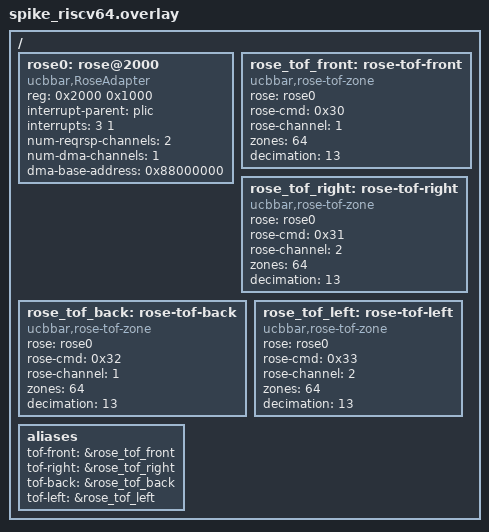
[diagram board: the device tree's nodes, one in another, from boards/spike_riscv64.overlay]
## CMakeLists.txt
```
# SPDX-License-Identifier: Apache-2.0
cmake_minimum_required(VERSION 3.20.0)
find_package(Zephyr REQUIRED HINTS $ENV{ZEPHYR_BASE})
project(rose_multisensor_probe)
target_sources(app PRIVATE src/main.c)
```

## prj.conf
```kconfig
# RoSE multizone-ToF data-collection probe (co-sim). Reads the 4 horizontal VL53L5CX zone
# grids over the RoSE bridge through the reusable ucbbar,rose-tof-zone driver.
CONFIG_SENSOR=y
CONFIG_PRINTK=y
CONFIG_BOOT_BANNER=n
# Match the (working) flight-controller image layout: with a tiny image __global_pointer$
# ends up >2KB from z_interrupt_stacks and the RISC-V GPREL relocation in the kernel's
# stacktrace code truncates at link. The C++ runtime + a large main stack grow .data/.bss
# so gp lands in range (spike_riscv64 forces the RISCV_GP choice on).
CONFIG_CPP=y
CONFIG_REQUIRES_FULL_LIBCPP=n
CONFIG_MAIN_STACK_SIZE=327680
```

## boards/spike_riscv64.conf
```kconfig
# RoSE co-sim: bridge driver + protocol + the multizone ToF virtual driver (bound by
# boards/spike_riscv64.overlay).
CONFIG_ROSE=y
CONFIG_ROSE_PROTOCOL=y
CONFIG_ROSE_SENSOR_TOF_ZONE=y

CONFIG_PICOLIBC=y
CONFIG_COMMON_LIBC_MALLOC=y
CONFIG_FPU=y
```

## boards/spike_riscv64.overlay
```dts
/* RoSE co-sim overlay for the multizone-ToF probe: the RoSE bridge adapter + the four
 * horizontal VL53L5CX multizone ToF sensors. Command IDs / reqrsp channels match
 * config_gym_IsaacCrazyflieMultiSensorEnv-v0.yaml (front 0x30/ch1, right 0x31/ch2,
 * back 0x32/ch1, left 0x33/ch2). The app binds them through the aliases tof_front/right/
 * back/left, exactly as a real board would bind st,vl53l5cx.
 */
/ {
	rose0: rose@2000 {
		compatible = "ucbbar,RoseAdapter";
		reg = <0x2000 0x1000>;
		interrupt-parent = <&plic>;
		interrupts = <3 1>;
		num-reqrsp-channels = <2>;
		num-dma-channels = <1>;
		dma-base-address = <0x88000000>;
		status = "okay";
	};

	rose_tof_front: rose-tof-front {
		compatible = "ucbbar,rose-tof-zone";
		rose = <&rose0>;
		rose-cmd = <0x30>;
		rose-channel = <1>;
		zones = <64>;
		decimation = <13>;
		status = "okay";
	};
	rose_tof_right: rose-tof-right {
		compatible = "ucbbar,rose-tof-zone";
		rose = <&rose0>;
		rose-cmd = <0x31>;
		rose-channel = <2>;
		zones = <64>;
		decimation = <13>;
		status = "okay";
	};
	rose_tof_back: rose-tof-back {
		compatible = "ucbbar,rose-tof-zone";
		rose = <&rose0>;
		rose-cmd = <0x32>;
		rose-channel = <1>;
		zones = <64>;
		decimation = <13>;
		status = "okay";
	};
	rose_tof_left: rose-tof-left {
		compatible = "ucbbar,rose-tof-zone";
		rose = <&rose0>;
		rose-cmd = <0x33>;
		rose-channel = <2>;
		zones = <64>;
		decimation = <13>;
		status = "okay";
	};

	aliases {
		tof-front = &rose_tof_front;
		tof-right = &rose_tof_right;
		tof-back  = &rose_tof_back;
		tof-left  = &rose_tof_left;
	};
};
```

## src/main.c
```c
/*
 * Copyright (c) 2026 UC Berkeley
 * SPDX-License-Identifier: Apache-2.0
 *
 * RoSE multizone-ToF data-collection probe. Validates that the guest can collect the four
 * horizontal VL53L5CX zone grids (front/right/back/left) over the RoSE bridge through the
 * REUSABLE ucbbar,rose-tof-zone driver + the standard Zephyr sensor API. Each control step it
 * batches all four sample_fetch (pipelined reqrsp issue) then all four channel_get, and prints
 * the per-direction nearest-wall distance (SENSOR_CHAN_DISTANCE = min zone). On real hardware
 * the same aliases bind to st,vl53l5cx unchanged.
 */
#include <zephyr/kernel.h>
#include <zephyr/device.h>
#include <zephyr/drivers/sensor.h>
#include <rose/rose_sensor.h>

#define ITERS 400

static const struct device *const tof_front = DEVICE_DT_GET(DT_ALIAS(tof_front));
static const struct device *const tof_right = DEVICE_DT_GET(DT_ALIAS(tof_right));
static const struct device *const tof_back  = DEVICE_DT_GET(DT_ALIAS(tof_back));
static const struct device *const tof_left  = DEVICE_DT_GET(DT_ALIAS(tof_left));

static float read_min(const struct device *dev)
{
	struct sensor_value v;

	if (sensor_channel_get(dev, SENSOR_CHAN_DISTANCE, &v) < 0) {
		return -1.0f;
	}
	return (float)sensor_value_to_double(&v);
}

int main(void)
{
	const struct device *devs[4] = { tof_front, tof_right, tof_back, tof_left };
	const char *names[4] = { "front", "right", "back", "left" };

	for (int i = 0; i < 4; i++) {
		if (!device_is_ready(devs[i])) {
			printk("rose_multisensor_probe: %s ToF not ready\n", names[i]);
			return -1;
		}
	}
	printk("rose_multisensor_probe: 4x VL53L5CX multizone ToF ready, collecting over RoSE\n");

	for (int it = 0; it < ITERS; it++) {
		/* Phase 1: issue all four zone-grid requests (pipelined). A decimated sensor
		 * returns -EAGAIN on non-refresh steps -> reuse its last grid. */
		bool fresh[4];
		for (int i = 0; i < 4; i++) {
			fresh[i] = (sensor_sample_fetch(devs[i]) == 0);
		}
		/* Phase 2: collect (blocking read on the first get) -> nearest wall per direction. */
		float d[4];
		for (int i = 0; i < 4; i++) {
			d[i] = read_min(devs[i]);
		}
		if (it % 20 == 0) {
			/* millimetres as integers (no float printf needed) */
			printk("iter=%3d  front=%4dmm  right=%4dmm  back=%4dmm  left=%4dmm  (fresh %d%d%d%d)\n",
			       it, (int)(d[0] * 1000), (int)(d[1] * 1000), (int)(d[2] * 1000),
			       (int)(d[3] * 1000), fresh[0], fresh[1], fresh[2], fresh[3]);
		}
	}
	printk("rose_multisensor_probe: done (%d steps)\n", ITERS);
	return 0;
}
```
